# FM33FH0XX register map
File version: 1.0
CPU: SC000 r1p0, little endian, no MPU, no FPU, 3 interrupt priority bits
Registers are 32-bit, read-write, reset 0x0 unless marked. A register's access mark holds for its fields unless they carry their own. Offsets are from the block's base; [hi:lo] are bit positions; {n}, {i} and the like mark numbered series.

## PMU — PMU module information
Base 0x40002000
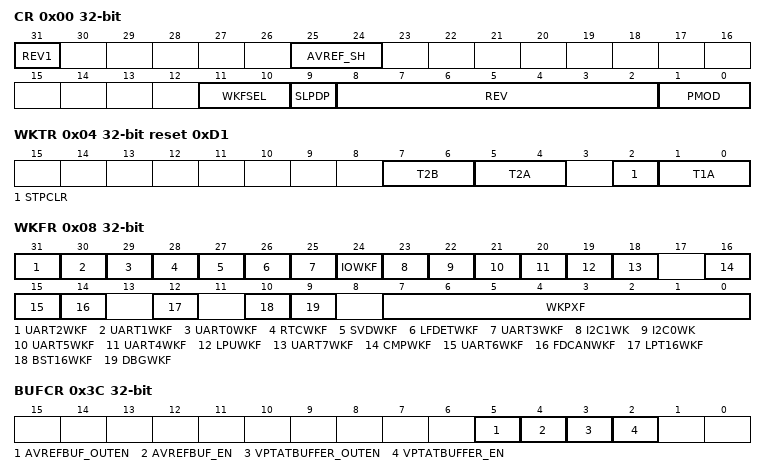
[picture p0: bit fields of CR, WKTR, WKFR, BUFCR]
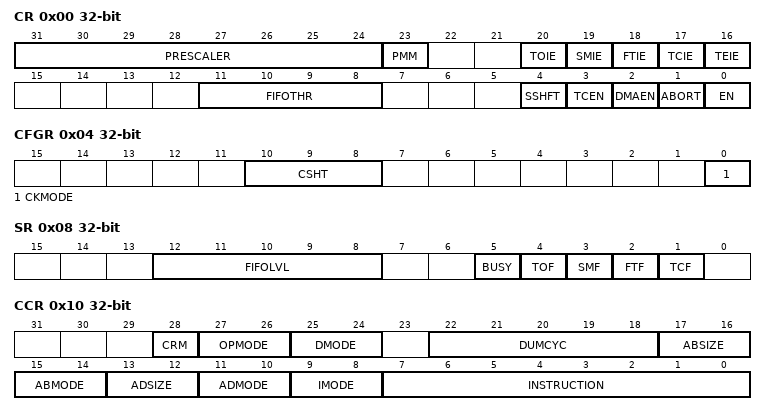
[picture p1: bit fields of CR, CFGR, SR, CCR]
0x00 CR
  [31] REV1 — REV1 field description
  [25:24] AVREF_SH — AVREF_SH field description
  [11:10] WKFSEL — WKFSEL field description
  [9] SLPDP — SLPDP field description
  [8:2] REV — REV field description
  [1:0] PMOD — PMOD field description
0x04 WKTR reset 0xD1
  [7:6] T2B — T2B field description
  [5:4] T2A — T2A field description
  [2] STPCLR — STPCLR field description
  [1:0] T1A — T1A field description
0x08 WKFR
  [31] UART2WKF ro — UART2WKF field description
  [30] UART1WKF ro — UART1WKF field description
  [29] UART0WKF ro — UART0WKF field description
  [28] RTCWKF ro — RTCWKF field description
  [27] SVDWKF ro — SVDWKF field description
  [26] LFDETWKF ro — LFDETWKF field description
  [25] UART3WKF ro — UART3WKF field description
  [24] IOWKF ro — IOWKF field description
  [23] I2C1WK ro — I2C1WK field description
  [22] I2C0WK ro — I2C0WK field description
  [21] UART5WKF ro — UART5WKF field description
  [20] UART4WKF ro — UART4WKF field description
  [19] LPUWKF ro — LPUWKF field description
  [18] UART7WKF ro — UART7WKF field description
  [16] CMPWKF ro — CMPWKF field description
  [15] UART6WKF ro — UART6WKF field description
  [14] FDCANWKF ro — FDCANWKF field description
  [12] LPT16WKF ro — LPT16WKF field description
  [10] BST16WKF ro — BST16WKF field description
  [9] DBGWKF — DBGWKF field description
  [7:0] WKPXF — WKPXF field description
0x0C IER
  [0] LPREIE — LPREIE field description
0x10 ISR
  [0] LPREIF — LPREIF field description
0x3C BUFCR
  [5] AVREFBUF_OUTEN — AVREFBUF_OUTEN field description
  [4] AVREFBUF_EN — AVREFBUF_EN field description
  [3] VPTATBUFFER_OUTEN — VPTATBUFFER_OUTEN field description
  [2] VPTATBUFFER_EN — VPTATBUFFER_EN field description
0x50 PTATCR
  [0] EN — EN field description

## QSPI — QSPI module information
Base 0x40000800
0x00 CR
  [31:24] PRESCALER — PRESCALER field description
  [23] PMM — PMM field description
  [20] TOIE — TOIE field description
  [19] SMIE — SMIE field description
  [18] FTIE — FTIE field description
  [17] TCIE — TCIE field description
  [16] TEIE — TEIE field description
  [11:8] FIFOTHR — FIFOTHR field description
  [4] SSHFT — SSHFT field description
  [3] TCEN — TCEN field description
  [2] DMAEN — DMAEN field description
  [1] ABORT — ABORT field description
  [0] EN — EN field description
0x04 CFGR
  [10:8] CSHT — CSHT field description
  [0] CKMODE — CKMODE field description
0x08 SR
  [12:8] FIFOLVL ro — FIFOLVL field description
  [5] BUSY ro — BUSY field description
  [4] TOF — TOF field description
  [3] SMF — SMF field description
  [2] FTF — FTF field description
  [1] TCF — TCF field description
0x0C DATALEN
  [31:0] LEN — LEN field description
0x10 CCR
  [28] CRM — CRM field description
  [27:26] OPMODE — OPMODE field description
  [25:24] DMODE — DMODE field description
  [22:18] DUMCYC — DUMCYC field description
  [17:16] ABSIZE — ABSIZE field description
  [15:14] ABMODE — ABMODE field description
  [13:12] ADSIZE — ADSIZE field description
  [11:10] ADMODE — ADMODE field description
  [9:8] IMODE — IMODE field description
  [7:0] INSTRUCTION — INSTRUCTION field description
0x14 ADDR
  [31:0] ADDR — ADDR field description
0x18 ABR
  [31:0] ABR — ABR field description
0x1C DATA
  [31:0] DATA ro — DATA field description
0x20 SMSK
  [31:0] SMSK — SMSK field description
0x24 SMAT
  [31:0] SMAT — SMAT field description
0x28 PITV
  [15:0] PITV — PITV field description
0x2C TOR
  [15:0] TO — TO field description

## RMU — RMU module information
Base 0x40002800
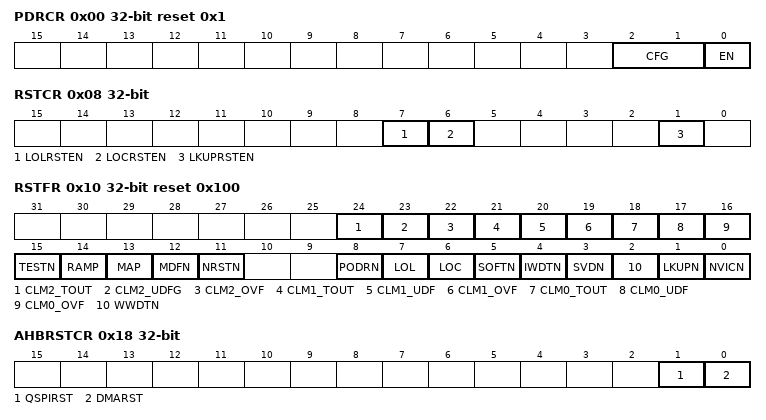
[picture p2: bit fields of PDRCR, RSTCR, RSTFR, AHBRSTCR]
0x00 PDRCR reset 0x1
  [2:1] CFG — CFG field description
  [0] EN — EN field description
0x08 RSTCR
  [7] LOLRSTEN — LOLRSTEN field description
  [6] LOCRSTEN — LOCRSTEN field description
  [1] LKUPRSTEN — LKUPRSTEN field description
0x0C SOFTRST
  [31:0] SOFTRST wo — SOFTRST field description
0x10 RSTFR reset 0x100
  [24] CLM2_TOUT — CLM2_TOUT field description
  [23] CLM2_UDFG — CLM2_UDFG field description
  [22] CLM2_OVF — CLM2_OVF field description
  [21] CLM1_TOUT — CLM1_TOUT field description
  [20] CLM1_UDF — CLM1_UDF field description
  [19] CLM1_OVF — CLM1_OVF field description
  [18] CLM0_TOUT — CLM0_TOUT field description
  [17] CLM0_UDF — CLM0_UDF field description
  [16] CLM0_OVF — CLM0_OVF field description
  [15] TESTN — TESTN field description
  [14] RAMP — RAMP field description
  [13] MAP — MAP field description
  [12] MDFN — MDFN field description
  [11] NRSTN — NRSTN field description
  [8] PODRN — PODRN field description
  [7] LOL — LOL field description
  [6] LOC — LOC field description
  [5] SOFTN — SOFTN field description
  [4] IWDTN — IWDTN field description
  [3] SVDN — SVDN field description
  [2] WWDTN — WWDTN field description
  [1] LKUPN — LKUPN field description
  [0] NVICN — NVICN field description
0x14 PRSTEN
  [31:0] EN wo — EN field description
0x18 AHBRSTCR
  [1] QSPIRST — QSPIRST field description
  [0] DMARST — DMARST field description
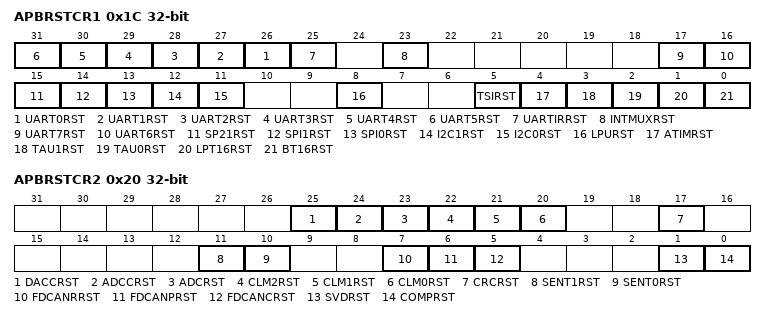
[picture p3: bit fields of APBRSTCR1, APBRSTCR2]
0x1C APBRSTCR1
  [n+26] UART{n}RST (n=0..5) — UART{n}RST field description
  [25] UARTIRRST — UARTIRRST field description
  [23] INTMUXRST — INTMUXRST field description
  [17] UART7RST — UART7RST field description
  [16] UART6RST — UART6RST field description
  [15] SP21RST — SP21RST field description
  [14] SPI1RST — SPI1RST field description
  [13] SPI0RST — SPI0RST field description
  [12] I2C1RST — I2C1RST field description
  [11] I2C0RST — I2C0RST field description
  [8] LPURST — LPURST field description
  [5] TSIRST — TSIRST field description
  [4] ATIMRST — ATIMRST field description
  [3] TAU1RST — TAU1RST field description
  [2] TAU0RST — TAU0RST field description
  [1] LPT16RST — LPT16RST field description
  [0] BT16RST — BT16RST field description
0x20 APBRSTCR2
  [25] DACCRST — DACCRST field description
  [24] ADCCRST — ADCCRST field description
  [23] ADCRST — ADCRST field description
  [22] CLM2RST — CLM2RST field description
  [21] CLM1RST — CLM1RST field description
  [20] CLM0RST — CLM0RST field description
  [17] CRCRST — CRCRST field description
  [11] SENT1RST — SENT1RST field description
  [10] SENT0RST — SENT0RST field description
  [7] FDCANRRST — FDCANRRST field description
  [6] FDCANPRST — FDCANPRST field description
  [5] FDCANCRST — FDCANCRST field description
  [1] SVDRST — SVDRST field description
  [0] COMPRST — COMPRST field description
